# GTC0_GTC_CFG3 register map
Vendor: Texas Instruments
Peripheral module from a debugger description file (folder am65x).
Registers are 32-bit, read-only, reset 0x0 unless marked. A register's access mark holds for its fields unless they carry their own. Offsets are as the file gives them; lines under a group give offsets from that group; [hi:lo] are bit positions; {n}, {i} and the like mark numbered series; 'fields as' and 'values as' point back to an identical list; <NAME> marks a mode.

## GTC0_GTC_CFG3
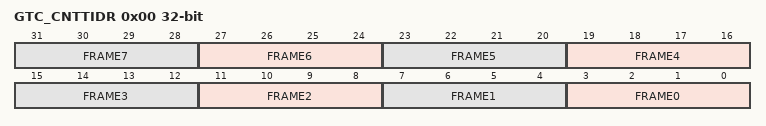
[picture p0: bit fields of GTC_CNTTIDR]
0x00 GTC_CNTTIDR — Indicates the implemented timers in the memory map and their features. Because the platform does not implement memory-mapped timers, this register is set to all 0s.
  [4n+3:4n] FRAME{n} (n=0..7) — Indicates the features of timer frame {n}
